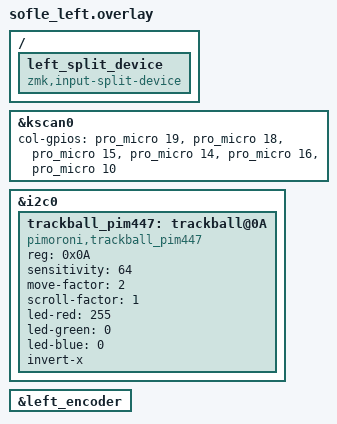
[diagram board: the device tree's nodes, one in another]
/*
 * Copyright (c) 2020 Ryan Cross
 *
 * SPDX-License-Identifier: MIT
 */

#include "sofle.dtsi"

&kscan0 {
    col-gpios
        = <&pro_micro 19 GPIO_ACTIVE_HIGH>
        , <&pro_micro 18 GPIO_ACTIVE_HIGH>
        , <&pro_micro 15 GPIO_ACTIVE_HIGH>
        , <&pro_micro 14 GPIO_ACTIVE_HIGH>
        , <&pro_micro 16 GPIO_ACTIVE_HIGH>
        , <&pro_micro 10 GPIO_ACTIVE_HIGH>
        ;
};

&i2c0 {
    status = "okay";
    
    trackball_pim447: trackball@0A {
        compatible = "pimoroni,trackball_pim447";
        reg = <0x0A>;
        sensitivity = <64>;  /* Range: 1-255 */
        move-factor = <2>;   /* Range: 1-10, scales cursor movement speed */
        scroll-factor = <1>; /* Range: 1-10, scales scrolling speed */
        
        /* Optional LED color (RGB values 0-255) */
        led-red = <255>;
        led-green = <0>;
        led-blue = <0>;
        
        /* Optional axis inversion */
        invert-x;  /* Uncomment to invert X axis */
        /* invert-y; */  /* Uncomment to invert Y axis */
    };
};

&left_encoder {
    status = "okay";
};

/ {
    left_split_device {
        compatible = "zmk,input-split-device";
    };
};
